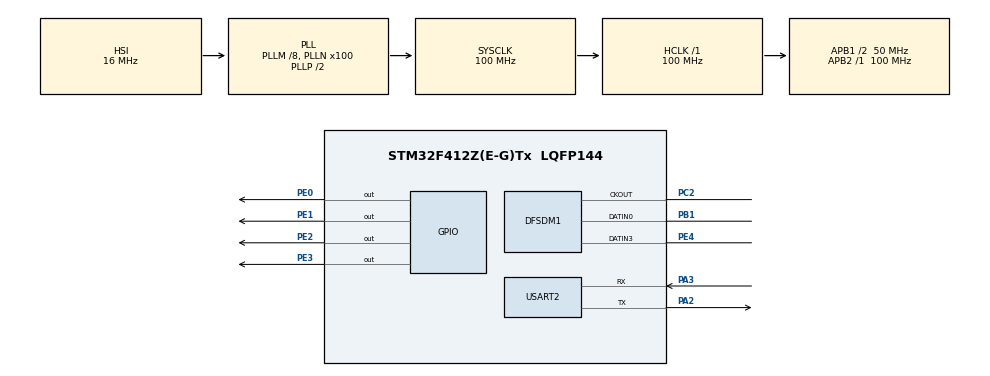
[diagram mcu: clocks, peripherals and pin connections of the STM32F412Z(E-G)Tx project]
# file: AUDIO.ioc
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DFSDM1.Divider=24
DFSDM1.DmaMode_reg_FIL0=ENABLE
DFSDM1.DmaMode_reg_FIL1=ENABLE
DFSDM1.ExtTriggerEdge_inj_FIL0=DFSDM_FILTER_EXT_TRIG_BOTH_EDGES
DFSDM1.ExtTriggerEdge_inj_FIL1=DFSDM_FILTER_EXT_TRIG_BOTH_EDGES
DFSDM1.ExtTrigger_inj_FIL0=DFSDM_FILTER_EXT_TRIG_TIM8_TRGO
DFSDM1.ExtTrigger_inj_FIL1=DFSDM_FILTER_EXT_TRIG_TIM8_TRGO
DFSDM1.FastMode_reg_FIL0=ENABLE
DFSDM1.FastMode_reg_FIL1=ENABLE
DFSDM1.FilterOrder_CH0=DFSDM_CHANNEL_SINC1_ORDER
DFSDM1.FilterOrder_CH3=DFSDM_CHANNEL_SINC1_ORDER
DFSDM1.Filter_injChannel0_FIL0=DFSDM_CHANNEL_0
DFSDM1.Filter_injChannel3_FIL0=__NULL
DFSDM1.Filter_injChannel3_FIL1=DFSDM_CHANNEL_3
DFSDM1.Filter_regChannel_FIL0=DFSDM_CHANNEL_0
DFSDM1.Filter_regChannel_FIL1=DFSDM_CHANNEL_3
DFSDM1.Filter_regContinuousMode_FIL0=DFSDM_CONTINUOUS_CONV_ON
DFSDM1.Fosr_FIL0=128
DFSDM1.Fosr_FIL1=128
DFSDM1.Oversampling_CH0=16
DFSDM1.Oversampling_CH3=16
DFSDM1.RightBitShift_CH0=0x02
DFSDM1.RightBitShift_CH3=0x2
DFSDM1.ScanMode_inj_FIL1=DISABLE
DFSDM1.Selection=DFSDM_CHANNEL_OUTPUT_CLOCK_AUDIO
DFSDM1.SincOrder_FIL0=DFSDM_FILTER_SINC3_ORDER
DFSDM1.SincOrder_FIL1=DFSDM_FILTER_SINC3_ORDER
DFSDM1.Trigger_inj_FIL0=DFSDM_FILTER_EXT_TRIGGER
DFSDM1.Trigger_inj_FIL1=DFSDM_FILTER_EXT_TRIGGER
DFSDM1.Type_spi_CH3=DFSDM_CHANNEL_SPI_FALLING
Dma.DFSDM1_FLT0.0.Direction=DMA_PERIPH_TO_MEMORY
Dma.DFSDM1_FLT0.0.FIFOMode=DMA_FIFOMODE_DISABLE
Dma.DFSDM1_FLT0.0.Instance=DMA2_Stream6
Dma.DFSDM1_FLT0.0.MemDataAlignment=DMA_MDATAALIGN_WORD
Dma.DFSDM1_FLT0.0.MemInc=DMA_MINC_ENABLE
Dma.DFSDM1_FLT0.0.Mode=DMA_CIRCULAR
Dma.DFSDM1_FLT0.0.PeriphDataAlignment=DMA_PDATAALIGN_WORD
Dma.DFSDM1_FLT0.0.PeriphInc=DMA_PINC_DISABLE
Dma.DFSDM1_FLT0.0.Priority=DMA_PRIORITY_HIGH
Dma.DFSDM1_FLT1.1.Direction=DMA_PERIPH_TO_MEMORY
Dma.DFSDM1_FLT1.1.FIFOMode=DMA_FIFOMODE_DISABLE
Dma.DFSDM1_FLT1.1.Instance=DMA2_Stream4
Dma.DFSDM1_FLT1.1.MemDataAlignment=DMA_MDATAALIGN_WORD
Dma.DFSDM1_FLT1.1.MemInc=DMA_MINC_ENABLE
Dma.DFSDM1_FLT1.1.Mode=DMA_CIRCULAR
Dma.DFSDM1_FLT1.1.PeriphDataAlignment=DMA_PDATAALIGN_WORD
Dma.DFSDM1_FLT1.1.PeriphInc=DMA_PINC_DISABLE
Dma.DFSDM1_FLT1.1.Priority=DMA_PRIORITY_HIGH
Dma.Request0=DFSDM1_FLT0
Dma.Request1=DFSDM1_FLT1
FREERTOS.Tasks01=defaultTask,24,128,StartDefaultTask,Default,NULL,Dynamic,NULL,NULL
FREERTOS.configCHECK_FOR_STACK_OVERFLOW=2
FREERTOS.configTOTAL_HEAP_SIZE=128000
Mcu.Family=STM32F4
Mcu.Name=STM32F412Z(E-G)Tx
Mcu.Package=LQFP144
NVIC.DMA2_Stream4_IRQn=true\:5\:0\:false\:false\:true\:false\:false\:true\:true
NVIC.DMA2_Stream6_IRQn=true\:5\:0\:false\:false\:true\:false\:false\:true\:true
NVIC.PriorityGroup=NVIC_PRIORITYGROUP_4
NVIC.TIM6_IRQn=true\:15\:0\:false\:false\:true\:false\:false\:true\:true
NVIC.TimeBase=TIM6_IRQn
NVIC.TimeBaseIP=TIM6
PA13.Mode=Serial_Wire
PA13.Signal=SYS_JTMS-SWDIO
PA14.Mode=Serial_Wire
PA14.Signal=SYS_JTCK-SWCLK
PA2.Mode=Asynchronous
PA2.Signal=USART2_TX
PA3.Mode=Asynchronous
PA3.Signal=USART2_RX
PB1.Signal=S_DATAIN0DFSDM1
PC2.Signal=S_CKOUTDFSDM1
PE0.Signal=GPIO_Output
PE1.Signal=GPIO_Output
PE2.Signal=GPIO_Output
PE3.Signal=GPIO_Output
PE4.Signal=S_DATAIN3DFSDM1
ProjectManager.HeapSize=0x200
ProjectManager.StackSize=0x400
ProjectManager.TargetToolchain=STM32CubeIDE
RCC.AHBFreq_Value=100000000
RCC.APB1CLKDivider=RCC_HCLK_DIV2
RCC.APB1Freq_Value=50000000
RCC.APB1TimFreq_Value=100000000
RCC.APB2Freq_Value=100000000
RCC.APB2TimFreq_Value=100000000
RCC.CortexFreq_Value=100000000
RCC.HCLKFreq_Value=100000000
RCC.PLLM=8
RCC.PLLN=100
RCC.SYSCLKFreq_VALUE=100000000
RCC.SYSCLKSource=RCC_SYSCLKSOURCE_PLLCLK
RCC.USBFreq_Value=100000000
RCC.VCOOutputFreq_Value=200000000
SH.S_CKOUTDFSDM1.0=DFSDM1_CKOUT,PDM_SPI_input_from_ch0_and_internal_clock
SH.S_CKOUTDFSDM1.1=DFSDM1_CKOUT,PDM_SPI_input_from_ch3_and_internal_clock
SH.S_DATAIN0DFSDM1.0=DFSDM1_DATIN0,PDM_SPI_input_from_ch0_and_internal_clock
SH.S_DATAIN3DFSDM1.0=DFSDM1_DATIN3,PDM_SPI_input_from_ch3_and_internal_clock
USART2.VirtualMode=VM_ASYNC
VP_FREERTOS_VS_CMSIS_V2.Mode=CMSIS_V2
VP_SYS_VS_tim6.Mode=TIM6
board=custom

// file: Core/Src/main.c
/* USER CODE BEGIN Header */
/**
  ******************************************************************************
  * @file           : main.c
  * @brief          : Main program body
  ******************************************************************************
  * @attention
  *
  * Copyright (c) 2025 STMicroelectronics.
  * All rights reserved.
  *
  * This software is licensed under terms that can be found in the LICENSE file
  * in the root directory of this software component.
  * If no LICENSE file comes with this software, it is provided AS-IS.
  *
  ******************************************************************************
  */
/* USER CODE END Header */
#include "main.h"
#include "cmsis_os.h"
#include "dfsdm.h"
#include "dma.h"
#include "usart.h"
#include "gpio.h"

void SystemClock_Config(void);
void PeriphCommonClock_Config(void);
void MX_FREERTOS_Init(void);
/* USER CODE BEGIN PFP */
/**
 * @brief  Half regular conversion complete callback.
 * @param  hdfsdm_filter : DFSDM filter handle.
 * @retval None
 */
void HAL_DFSDM_FilterRegConvHalfCpltCallback(DFSDM_Filter_HandleTypeDef *hdfsdm_filter)
{
  /* Forward callback to audio recorder */
  extern void audio_recorder_half_complete_callback(void);
  audio_recorder_half_complete_callback();
}

/**
 * @brief  Regular conversion complete callback.
 * @param  hdfsdm_filter : DFSDM filter handle.
 * @retval None
 */
void HAL_DFSDM_FilterRegConvCpltCallback(DFSDM_Filter_HandleTypeDef *hdfsdm_filter)
{
  /* Forward callback to audio recorder */
  extern void audio_recorder_full_complete_callback(void);
  audio_recorder_full_complete_callback();
}

/* USER CODE END PFP */

int main(void)
{

  /* MCU Configuration--------------------------------------------------------*/

  /* Reset of all peripherals, Initializes the Flash interface and the Systick. */
  HAL_Init();

  /* Configure the system clock */
  SystemClock_Config();

  /* Configure the peripherals common clocks */
  PeriphCommonClock_Config();

  /* Initialize all configured peripherals */
  MX_GPIO_Init();
  MX_DMA_Init();
  MX_USART2_UART_Init();
  MX_DFSDM1_Init();

  /* Init scheduler */
  osKernelInitialize();

  /* Call init function for freertos objects (in cmsis_os2.c) */
  MX_FREERTOS_Init();

  /* Start scheduler */
  osKernelStart();

  /* We should never get here as control is now taken by the scheduler */

  /* Infinite loop */
  while (1)
  {

  }
}

void SystemClock_Config(void)
{
  RCC_OscInitTypeDef RCC_OscInitStruct = {0};
  RCC_ClkInitTypeDef RCC_ClkInitStruct = {0};

  /** Macro to configure the PLL multiplication factor
  */
  __HAL_RCC_DFSDM1AUDIO_CONFIG(RCC_DFSDM1AUDIOCLKSOURCE_I2SAPB1);

  /** Configure the main internal regulator output voltage
  */
  __HAL_RCC_PWR_CLK_ENABLE();
  __HAL_PWR_VOLTAGESCALING_CONFIG(PWR_REGULATOR_VOLTAGE_SCALE1);

  /** Initializes the RCC Oscillators according to the specified parameters
  * in the RCC_OscInitTypeDef structure.
  */
  RCC_OscInitStruct.OscillatorType = RCC_OSCILLATORTYPE_HSI;
  RCC_OscInitStruct.HSIState = RCC_HSI_ON;
  RCC_OscInitStruct.HSICalibrationValue = RCC_HSICALIBRATION_DEFAULT;
  RCC_OscInitStruct.PLL.PLLState = RCC_PLL_ON;
  RCC_OscInitStruct.PLL.PLLSource = RCC_PLLSOURCE_HSI;
  RCC_OscInitStruct.PLL.PLLM = 8;
  RCC_OscInitStruct.PLL.PLLN = 100;
  RCC_OscInitStruct.PLL.PLLP = RCC_PLLP_DIV2;
  RCC_OscInitStruct.PLL.PLLQ = 2;
  RCC_OscInitStruct.PLL.PLLR = 2;
  if (HAL_RCC_OscConfig(&RCC_OscInitStruct) != HAL_OK)
  {
    Error_Handler();
  }

  /** Initializes the CPU, AHB and APB buses clocks
  */
  RCC_ClkInitStruct.ClockType = RCC_CLOCKTYPE_HCLK|RCC_CLOCKTYPE_SYSCLK
                              |RCC_CLOCKTYPE_PCLK1|RCC_CLOCKTYPE_PCLK2;
  RCC_ClkInitStruct.SYSCLKSource = RCC_SYSCLKSOURCE_PLLCLK;
  RCC_ClkInitStruct.AHBCLKDivider = RCC_SYSCLK_DIV1;
  RCC_ClkInitStruct.APB1CLKDivider = RCC_HCLK_DIV2;
  RCC_ClkInitStruct.APB2CLKDivider = RCC_HCLK_DIV1;

  if (HAL_RCC_ClockConfig(&RCC_ClkInitStruct, FLASH_LATENCY_3) != HAL_OK)
  {
    Error_Handler();
  }
}

void PeriphCommonClock_Config(void)
{
  RCC_PeriphCLKInitTypeDef PeriphClkInitStruct = {0};

  /** Initializes the peripherals clock
  */
  PeriphClkInitStruct.PeriphClockSelection = RCC_PERIPHCLK_PLLI2S|RCC_PERIPHCLK_I2S_APB1
                              |RCC_PERIPHCLK_DFSDM1|RCC_PERIPHCLK_DFSDM1_AUDIO;
  PeriphClkInitStruct.PLLI2S.PLLI2SN = 192;
  PeriphClkInitStruct.PLLI2S.PLLI2SM = 16;
  PeriphClkInitStruct.PLLI2S.PLLI2SR = 2;
  PeriphClkInitStruct.PLLI2S.PLLI2SQ = 2;
  PeriphClkInitStruct.Dfsdm1ClockSelection = RCC_DFSDM1CLKSOURCE_APB2;
  PeriphClkInitStruct.Dfsdm1AudioClockSelection = RCC_DFSDM1AUDIOCLKSOURCE_I2SAPB1;
  PeriphClkInitStruct.PLLI2SSelection = RCC_PLLI2SCLKSOURCE_PLLSRC;
  PeriphClkInitStruct.I2sApb1ClockSelection = RCC_I2SAPB1CLKSOURCE_PLLI2S;
  if (HAL_RCCEx_PeriphCLKConfig(&PeriphClkInitStruct) != HAL_OK)
  {
    Error_Handler();
  }
}

void HAL_TIM_PeriodElapsedCallback(TIM_HandleTypeDef *htim)
{
  if (htim->Instance == TIM6) {
    HAL_IncTick();
  }
}

void Error_Handler(void)
{
  __disable_irq();
  while (1)
  {
  }
}

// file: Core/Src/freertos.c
/* USER CODE BEGIN Header */
/**
  ******************************************************************************
  * File Name          : freertos.c
  * Description        : Code for freertos applications
  ******************************************************************************
  * @attention
  *
  * Copyright (c) 2025 STMicroelectronics.
  * All rights reserved.
  *
  * This software is licensed under terms that can be found in the LICENSE file
  * in the root directory of this software component.
  * If no LICENSE file comes with this software, it is provided AS-IS.
  *
  ******************************************************************************
  */
/* USER CODE END Header */

#include "FreeRTOS.h"
#include "task.h"
#include "main.h"
#include "cmsis_os.h"

/* USER CODE BEGIN Includes */
#include "MainApplication.h"
/* USER CODE END Includes */

/* Definitions for defaultTask */
osThreadId_t defaultTaskHandle;
const osThreadAttr_t defaultTask_attributes = {
  .name = "defaultTask",
  .stack_size = 128 * 4,
  .priority = (osPriority_t) osPriorityNormal,
};

void StartDefaultTask(void *argument);

void MX_FREERTOS_Init(void); /* (MISRA C 2004 rule 8.1) */

/* Hook prototypes */
void vApplicationStackOverflowHook(xTaskHandle xTask, signed char *pcTaskName);

/* USER CODE BEGIN 4 */
void vApplicationStackOverflowHook(xTaskHandle xTask, signed char *pcTaskName)
{
   /* Run time stack overflow checking is performed if
   configCHECK_FOR_STACK_OVERFLOW is defined to 1 or 2. This hook function is
   called if a stack overflow is detected. */
}
/* USER CODE END 4 */

void MX_FREERTOS_Init(void) {
  /* USER CODE BEGIN Init */
  ApplicationInit();
  /* USER CODE END Init */

  /* Create the thread(s) */
  /* creation of defaultTask */
  defaultTaskHandle = osThreadNew(StartDefaultTask, NULL, &defaultTask_attributes);

  /* USER CODE BEGIN RTOS_THREADS */
  /* add threads, ... */
  ApplicationRun();
  /* USER CODE END RTOS_THREADS */

}

void StartDefaultTask(void *argument)
{
  for(;;)
  {
    osDelay(1);
  }
}
